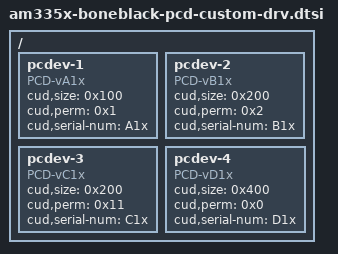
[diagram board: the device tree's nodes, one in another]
/ {

	pcdev-1 {
		compatible = "PCD-vA1x", "PCD-vB1x";
		cud,size = <0x100>;
		cud,perm = <0x1>;
		cud,serial-num = "A1x";
	};

	pcdev-2 {
		compatible = "PCD-vB1x";
		cud,size = <0x200>;
		cud,perm = <0x2>;
		cud,serial-num = "B1x";
	};

	pcdev-3 {
		compatible = "PCD-vC1x";
		cud,size = <0x200>;
		cud,perm = <0x11>;
		cud,serial-num = "C1x";
	};

	pcdev-4 {
		compatible = "PCD-vD1x";
		cud,size = <0x400>;
		cud,perm = <0x0>;
		cud,serial-num = "D1x";
	};
};
